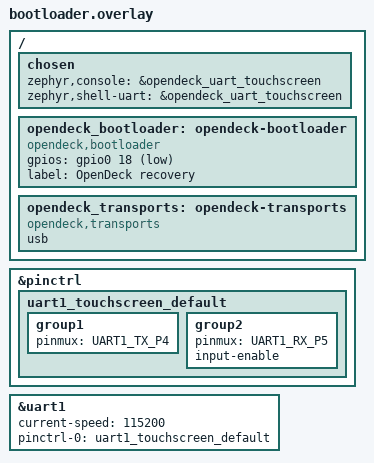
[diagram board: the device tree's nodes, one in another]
#include <zephyr/dt-bindings/pinctrl/rpi-pico-rp2040-pinctrl.h>

&pinctrl {
    uart1_touchscreen_default: uart1_touchscreen_default {
        group1 {
            pinmux = <UART1_TX_P4>;
        };

        group2 {
            pinmux = <UART1_RX_P5>;
            input-enable;
        };
    };
};

&uart1 {
    current-speed = <115200>;
    status = "okay";
    pinctrl-0 = <&uart1_touchscreen_default>;
    pinctrl-names = "default";
};

/ {
    chosen {
        zephyr,console = &opendeck_uart_touchscreen;
        zephyr,shell-uart = &opendeck_uart_touchscreen;
    };

    opendeck_bootloader: opendeck-bootloader {
        compatible = "opendeck,bootloader";
        gpios = <&gpio0 18 (GPIO_ACTIVE_LOW | GPIO_PULL_UP)>;
        label = "OpenDeck recovery";
    };

    opendeck_transports: opendeck-transports {
        compatible = "opendeck,transports";
        usb;
    };
};
